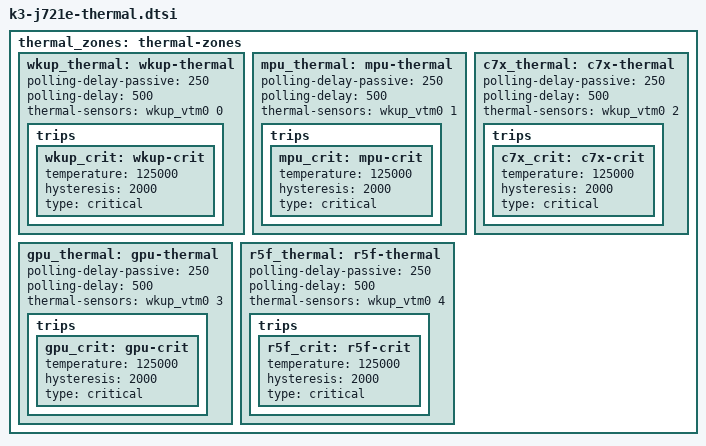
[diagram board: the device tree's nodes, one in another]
// SPDX-License-Identifier: GPL-2.0

#include <dt-bindings/thermal/thermal.h>

thermal_zones: thermal-zones {
	wkup_thermal: wkup-thermal {
		polling-delay-passive = <250>; /* milliseconds */
		polling-delay = <500>; /* milliseconds */
		thermal-sensors = <&wkup_vtm0 0>;

		trips {
			wkup_crit: wkup-crit {
				temperature = <125000>; /* milliCelsius */
				hysteresis = <2000>; /* milliCelsius */
				type = "critical";
			};
		};
	};

	mpu_thermal: mpu-thermal {
		polling-delay-passive = <250>; /* milliseconds */
		polling-delay = <500>; /* milliseconds */
		thermal-sensors = <&wkup_vtm0 1>;

		trips {
			mpu_crit: mpu-crit {
				temperature = <125000>; /* milliCelsius */
				hysteresis = <2000>; /* milliCelsius */
				type = "critical";
			};
		};
	};

	c7x_thermal: c7x-thermal {
		polling-delay-passive = <250>; /* milliseconds */
		polling-delay = <500>; /* milliseconds */
		thermal-sensors = <&wkup_vtm0 2>;

		trips {
			c7x_crit: c7x-crit {
				temperature = <125000>; /* milliCelsius */
				hysteresis = <2000>; /* milliCelsius */
				type = "critical";
			};
		};
	};

	gpu_thermal: gpu-thermal {
		polling-delay-passive = <250>; /* milliseconds */
		polling-delay = <500>; /* milliseconds */
		thermal-sensors = <&wkup_vtm0 3>;

		trips {
			gpu_crit: gpu-crit {
				temperature = <125000>; /* milliCelsius */
				hysteresis = <2000>; /* milliCelsius */
				type = "critical";
			};
		};
	};

	r5f_thermal: r5f-thermal {
		polling-delay-passive = <250>; /* milliseconds */
		polling-delay = <500>; /* milliseconds */
		thermal-sensors = <&wkup_vtm0 4>;

		trips {
			r5f_crit: r5f-crit {
				temperature = <125000>; /* milliCelsius */
				hysteresis = <2000>; /* milliCelsius */
				type = "critical";
			};
		};
	};
};
